VERSION ""

NS_ :

BS_:

BU_: EON XXX INTERCEPTOR ANY ACTUATOR SAFETY

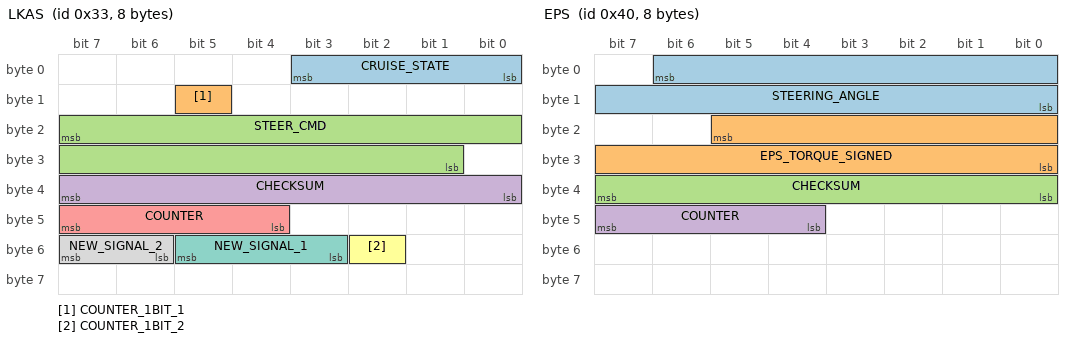
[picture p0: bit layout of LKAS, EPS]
BO_ 51 LKAS: 8 XXX
 SG_ CRUISE_STATE : 3|4@0+ (1,0) [0|15] "" XXX
 SG_ COUNTER_1BIT_1 : 13|1@0+ (1,0) [0|1] "" XXX
 SG_ STEER_CMD : 23|15@0+ (0.1,-1450) [0|32767] "" XXX
 SG_ CHECKSUM : 39|8@0+ (1,0) [0|255] "" XXX
 SG_ COUNTER : 47|4@0+ (1,0) [0|15] "" XXX
 SG_ COUNTER_1BIT_2 : 50|1@0+ (1,0) [0|1] "" XXX
 SG_ NEW_SIGNAL_1 : 53|3@0+ (1,0) [0|7] "" XXX
 SG_ NEW_SIGNAL_2 : 55|2@0+ (1,0) [0|3] "" XXX

BO_ 64 EPS: 8 XXX
 SG_ STEERING_ANGLE : 6|15@0- (0.01,0) [0|32767] "" XXX
 SG_ EPS_TORQUE_SIGNED : 21|14@0- (0.1,0) [0|16383] "" XXX
 SG_ CHECKSUM : 39|8@0+ (1,0) [0|255] "" XXX
 SG_ COUNTER : 47|4@0+ (1,0) [0|15] "" XXX

BO_ 70 STARTUP2: 8 XXX
 SG_ NEW_SIGNAL_1 : 53|14@0- (1,0) [0|16383] "" XXX

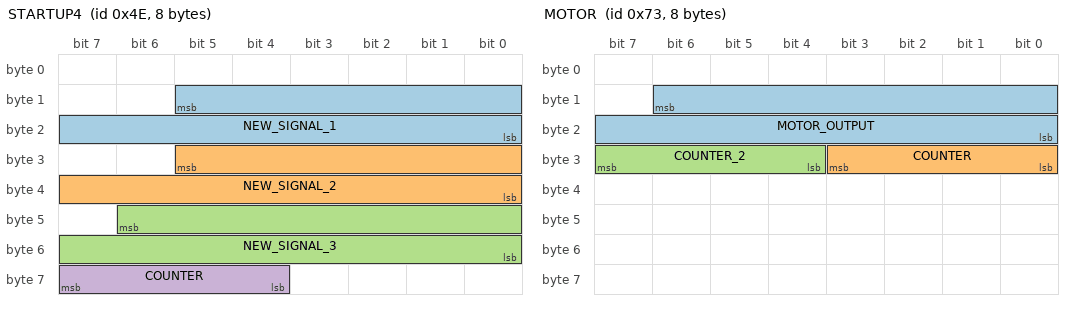
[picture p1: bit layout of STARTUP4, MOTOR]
BO_ 78 STARTUP4: 8 XXX
 SG_ NEW_SIGNAL_1 : 13|14@0- (1,0) [0|16383] "" XXX
 SG_ NEW_SIGNAL_2 : 29|14@0- (1,0) [0|16383] "" XXX
 SG_ NEW_SIGNAL_3 : 46|15@0- (1,0) [0|32767] "" XXX
 SG_ COUNTER : 63|4@0+ (1,0) [0|15] "" XXX

BO_ 81 STEER_RELATED: 8 XXX
 SG_ STEERING_RELATED : 7|16@0- (0.1,0) [0|65535] "" XXX

BO_ 98 NEW_MSG_62: 64 XXX

BO_ 115 MOTOR: 8 XXX
 SG_ MOTOR_OUTPUT : 14|15@0- (1,0) [0|32767] "" XXX
 SG_ COUNTER : 27|4@0+ (1,0) [0|15] "" XXX
 SG_ COUNTER_2 : 31|4@0+ (1,0) [0|15] "" XXX

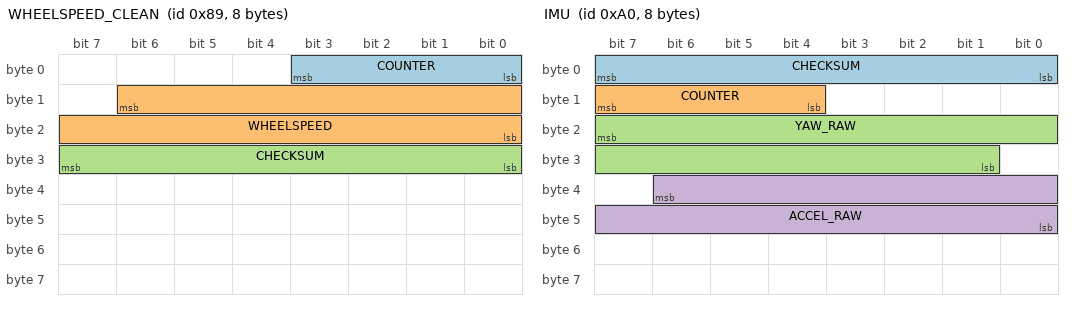
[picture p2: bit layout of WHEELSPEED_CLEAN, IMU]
BO_ 137 WHEELSPEED_CLEAN: 8 XXX
 SG_ COUNTER : 3|4@0+ (1,0) [0|15] "" XXX
 SG_ WHEELSPEED : 14|15@0+ (0.01,0) [0|32767] "" XXX
 SG_ CHECKSUM : 31|8@0+ (1,0) [0|255] "" XXX

BO_ 160 IMU: 8 XXX
 SG_ CHECKSUM : 7|8@0+ (1,0) [0|255] "" XXX
 SG_ COUNTER : 15|4@0+ (1,0) [0|15] "" XXX
 SG_ YAW_RAW : 23|15@0- (1,0) [0|32767] "" XXX
 SG_ ACCEL_RAW : 38|15@0- (1,0) [0|32767] "" XXX

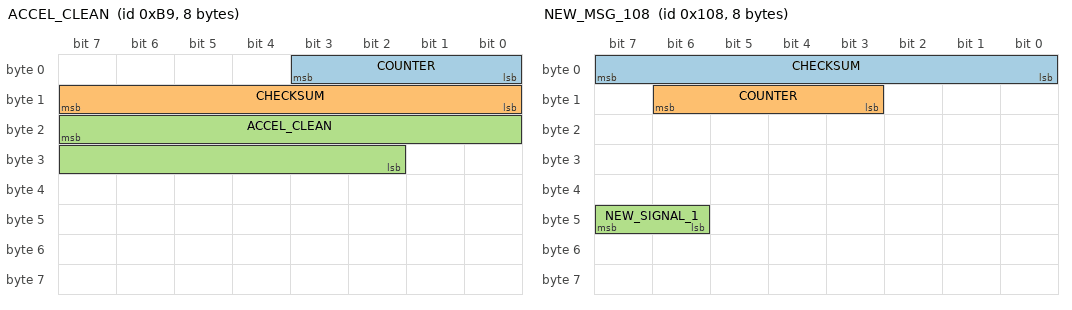
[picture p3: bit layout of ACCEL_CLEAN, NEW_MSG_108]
BO_ 185 ACCEL_CLEAN: 8 XXX
 SG_ COUNTER : 3|4@0+ (1,0) [0|15] "" XXX
 SG_ CHECKSUM : 15|8@0+ (1,0) [0|255] "" XXX
 SG_ ACCEL_CLEAN : 23|14@0- (1,0) [0|16383] "" XXX

BO_ 246 STARTUP3: 8 XXX
 SG_ NEW_SIGNAL_1 : 47|16@0- (1,0) [0|65535] "" XXX

BO_ 257 PEDALS: 64 XXX
 SG_ BRAKE_PRESSURE2 : 167|16@0+ (0.0002,0) [0|65535] "" XXX
 SG_ BRAKE_PRESSURE : 191|16@0+ (0.0002,0) [0|65535] "" XXX

BO_ 264 NEW_MSG_108: 8 XXX
 SG_ CHECKSUM : 7|8@0+ (1,0) [0|255] "" XXX
 SG_ COUNTER : 14|4@0+ (1,0) [0|15] "" XXX
 SG_ NEW_SIGNAL_1 : 47|2@0+ (1,0) [0|3] "" XXX

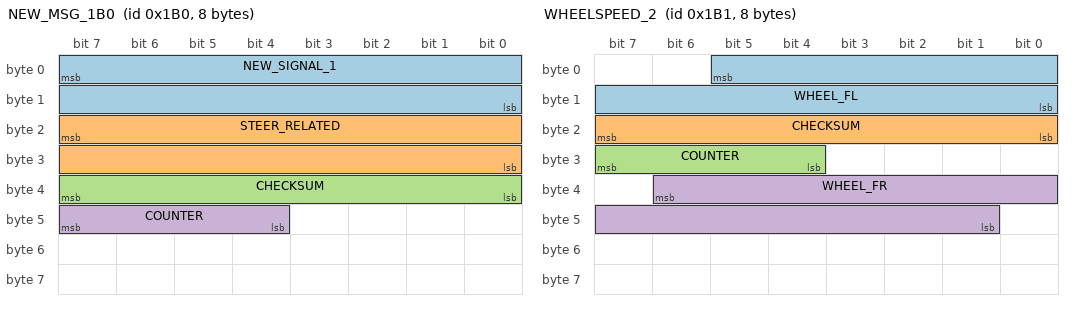
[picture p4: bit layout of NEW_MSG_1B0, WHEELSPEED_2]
BO_ 432 NEW_MSG_1B0: 8 XXX
 SG_ NEW_SIGNAL_1 : 7|16@0- (1,0) [0|65535] "" XXX
 SG_ STEER_RELATED : 23|16@0- (0.1,0) [0|65535] "" XXX
 SG_ CHECKSUM : 39|8@0+ (1,0) [0|255] "" XXX
 SG_ COUNTER : 47|4@0+ (1,0) [0|15] "" XXX

BO_ 433 WHEELSPEED_2: 8 XXX
 SG_ WHEEL_FL : 5|14@0+ (0.01,0) [0|16383] "" XXX
 SG_ CHECKSUM : 16|8@1+ (1,0) [0|255] "" XXX
 SG_ COUNTER : 31|4@0+ (1,0) [0|15] "" XXX
 SG_ WHEEL_FR : 38|14@0+ (0.01,0) [0|16383] "" XXX

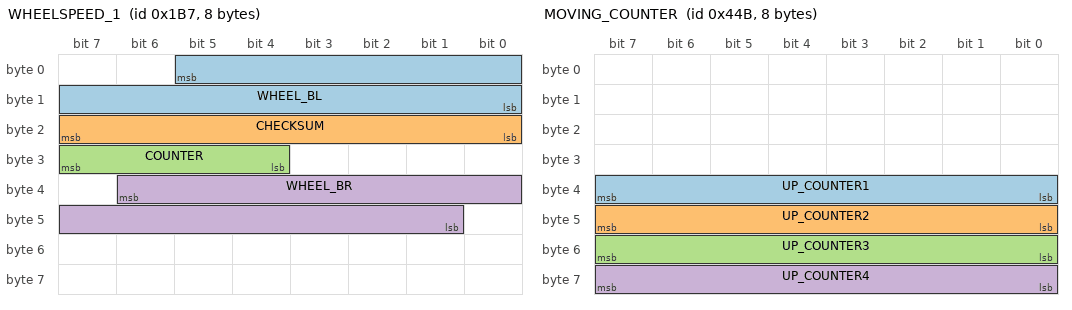
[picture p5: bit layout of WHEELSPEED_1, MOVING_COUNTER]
BO_ 439 WHEELSPEED_1: 8 XXX
 SG_ WHEEL_BL : 5|14@0+ (0.01,0) [0|16383] "" XXX
 SG_ CHECKSUM : 16|8@1+ (1,0) [0|255] "" XXX
 SG_ COUNTER : 31|4@0+ (1,0) [0|15] "" XXX
 SG_ WHEEL_BR : 38|14@0+ (0.01,0) [0|16383] "" XXX

BO_ 444 STARTUP1: 8 XXX
 SG_ NEW_SIGNAL_1 : 7|6@0+ (1,0) [0|63] "" XXX

BO_ 955 STARTUP5: 8 XXX
 SG_ NEW_SIGNAL_1 : 48|9@0+ (1,0) [0|511] "" XXX

BO_ 1099 MOVING_COUNTER: 8 XXX
 SG_ UP_COUNTER1 : 39|8@0+ (1,0) [0|255] "" XXX
 SG_ UP_COUNTER2 : 47|8@0+ (1,0) [0|255] "" XXX
 SG_ UP_COUNTER3 : 55|8@0+ (1,0) [0|255] "" XXX
 SG_ UP_COUNTER4 : 63|8@0+ (1,0) [0|255] "" XXX

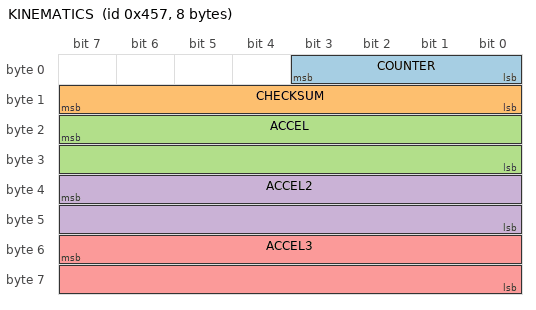
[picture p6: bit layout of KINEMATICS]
BO_ 1111 KINEMATICS: 8 XXX
 SG_ COUNTER : 3|4@0+ (1,0) [0|15] "" XXX
 SG_ CHECKSUM : 15|8@0+ (1,0) [0|255] "" XXX
 SG_ ACCEL : 23|16@0- (1,0) [0|65535] "" XXX
 SG_ ACCEL2 : 39|16@0- (1,0) [0|65535] "" XXX
 SG_ ACCEL3 : 55|16@0- (0.5,0) [0|65535] "" XXX

CM_ SG_ 64 EPS_TORQUE_SIGNED "STEERING TOUCH > VALUE 10";
VAL_ 51 CRUISE_STATE 7 "ENABLE";
